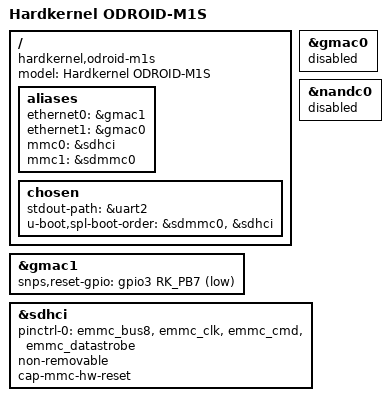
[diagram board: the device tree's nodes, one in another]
/*
 * SPDX-License-Identifier:     GPL-2.0+
 *
 * (C) Copyright 2021 Hardkernel Co., Ltd
 */

/dts-v1/;
#include "rk3568-evb.dts"

/ {
	model = "Hardkernel ODROID-M1S";
	compatible = "hardkernel,odroid-m1s", "rockchip,rk3568";

	aliases {
		ethernet0 = &gmac1;
		ethernet1 = &gmac0;
		mmc0 = &sdhci;
		mmc1 = &sdmmc0;
	};

	chosen {
		stdout-path = &uart2;
		u-boot,spl-boot-order = &sdmmc0, &sdhci;
	};

	/delete-node/ adc-keys;
};

&gmac0 {
	status = "disabled";
};

&gmac1 {
	snps,reset-gpio = <&gpio3 RK_PB7 GPIO_ACTIVE_LOW>;
	status = "okay";
};

&nandc0 {
	status = "disabled";
};

&sdhci {
	pinctrl-names = "default";
	pinctrl-0 = <&emmc_bus8
		     &emmc_clk
		     &emmc_cmd
		     &emmc_datastrobe>;
	non-removable;
	cap-mmc-hw-reset;
};
